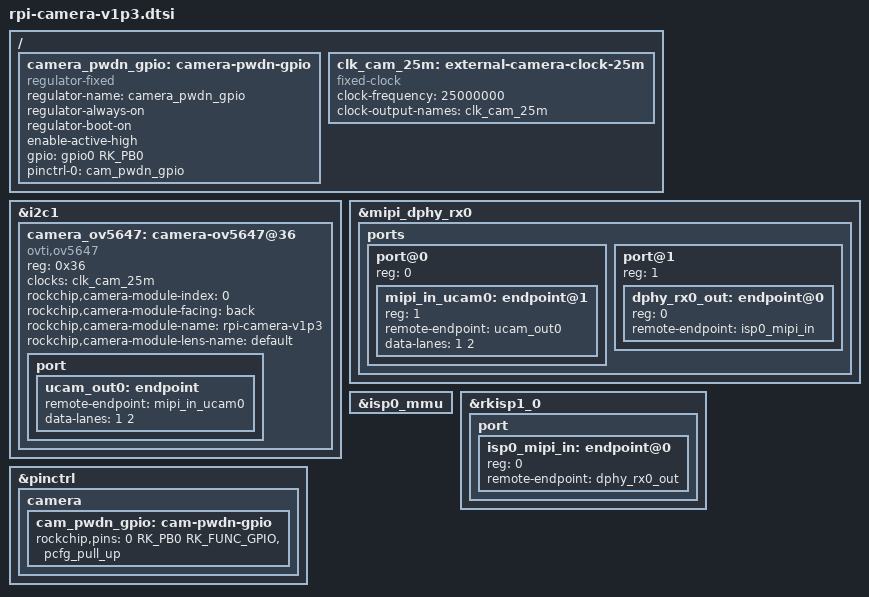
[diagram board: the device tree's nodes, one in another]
#include <dt-bindings/gpio/gpio.h>
#include <dt-bindings/pinctrl/rockchip.h>

/ {
	camera_pwdn_gpio: camera-pwdn-gpio {
		status = "okay";
		compatible = "regulator-fixed";
		regulator-name = "camera_pwdn_gpio";
		regulator-always-on;
		regulator-boot-on;
		enable-active-high;
		gpio = <&gpio0 RK_PB0 GPIO_ACTIVE_HIGH>;
		pinctrl-names = "default";
		pinctrl-0 = <&cam_pwdn_gpio>;
	};
	
	clk_cam_25m: external-camera-clock-25m {
		status = "okay";
		compatible = "fixed-clock";
		clock-frequency = <25000000>;
		clock-output-names = "clk_cam_25m";
		#clock-cells = <0>;
	};
};
/* V1.0 use I2C1 */
&i2c1{
	status = "okay";
	#address-cells = <1>;
	#size-cells = <0>;

	camera_ov5647: camera-ov5647@36 {
		status = "okay";
		compatible = "ovti,ov5647";
		reg = <0x36>;

		clocks = <&clk_cam_25m>;
		clock-names = "xclk";

		rockchip,camera-module-index = <0>;
		rockchip,camera-module-facing = "back";
		rockchip,camera-module-name = "rpi-camera-v1p3";
		rockchip,camera-module-lens-name = "default";

		port {
			ucam_out0: endpoint {
				remote-endpoint = <&mipi_in_ucam0>;
				data-lanes = <1 2>;
			};
		};
	};
};

&mipi_dphy_rx0{
	status = "okay";

	ports {
		#address-cells = <1>;
		#size-cells = <0>;

		port@0 {
			reg = <0>;
			#address-cells = <1>;
			#size-cells = <0>;

			mipi_in_ucam0: endpoint@1 {
				reg = <1>;
				remote-endpoint = <&ucam_out0>;
				data-lanes = <1 2>;
			};
		};

		port@1 {
			reg = <1>;
			#address-cells = <1>;
			#size-cells = <0>;

			dphy_rx0_out: endpoint@0 {
				reg = <0>;
				remote-endpoint = <&isp0_mipi_in>;
			};
		};
	};
};

&isp0_mmu{
	status = "okay";
};

&rkisp1_0{
	status = "okay";

	port {
		#address-cells = <1>;
		#size-cells = <0>;

		isp0_mipi_in: endpoint@0 {
			reg = <0>;
			remote-endpoint = <&dphy_rx0_out>;
		};
	};
};

&pinctrl{
	camera {
		cam_pwdn_gpio: cam-pwdn-gpio {
			rockchip,pins = <0 RK_PB0 RK_FUNC_GPIO &pcfg_pull_up>;
		};
	};
};

